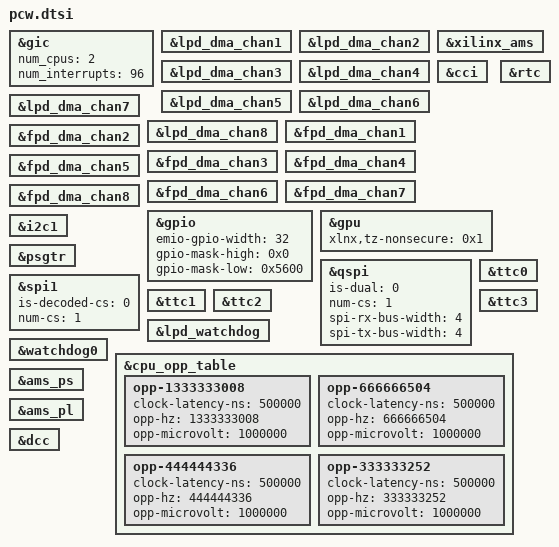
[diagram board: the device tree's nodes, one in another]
/*
 * CAUTION: This file is automatically generated by Xilinx.
 * Version: XSCT 2024.1
 * Today is: Thu Nov  7 23:48:31 2024
 */


&gic {
	num_cpus = <2>;
	num_interrupts = <96>;
};
&lpd_dma_chan1 {
	status = "okay";
};
&lpd_dma_chan2 {
	status = "okay";
};
&lpd_dma_chan3 {
	status = "okay";
};
&lpd_dma_chan4 {
	status = "okay";
};
&lpd_dma_chan5 {
	status = "okay";
};
&lpd_dma_chan6 {
	status = "okay";
};
&lpd_dma_chan7 {
	status = "okay";
};
&lpd_dma_chan8 {
	status = "okay";
};
&xilinx_ams {
	status = "okay";
};
&cci {
	status = "okay";
};
&fpd_dma_chan1 {
	status = "okay";
};
&fpd_dma_chan2 {
	status = "okay";
};
&fpd_dma_chan3 {
	status = "okay";
};
&fpd_dma_chan4 {
	status = "okay";
};
&fpd_dma_chan5 {
	status = "okay";
};
&fpd_dma_chan6 {
	status = "okay";
};
&fpd_dma_chan7 {
	status = "okay";
};
&fpd_dma_chan8 {
	status = "okay";
};
&gpio {
	emio-gpio-width = <32>;
	gpio-mask-high = <0x0>;
	gpio-mask-low = <0x5600>;
	status = "okay";
};
&gpu {
	status = "okay";
	xlnx,tz-nonsecure = <0x1>;
};
&i2c1 {
	status = "okay";
};
&qspi {
	is-dual = <0>;
	num-cs = <1>;
	spi-rx-bus-width = <4>;
	spi-tx-bus-width = <4>;
	status = "okay";
};
&rtc {
	status = "okay";
};
&psgtr {
	status = "okay";
};
&spi1 {
	is-decoded-cs = <0>;
	num-cs = <1>;
	status = "okay";
};
&ttc0 {
	status = "okay";
};
&ttc1 {
	status = "okay";
};
&ttc2 {
	status = "okay";
};
&ttc3 {
	status = "okay";
};
&lpd_watchdog {
	status = "okay";
};
&watchdog0 {
	status = "okay";
};
&cpu_opp_table {
	/delete-node/ opp00 ;
	/delete-node/ opp01 ;
	/delete-node/ opp02 ;
	/delete-node/ opp03 ;
	opp-1333333008 {
		clock-latency-ns = <500000>;
		opp-hz = /bits/ 64 <1333333008>;
		opp-microvolt = <1000000>;
	};
	opp-666666504 {
		clock-latency-ns = <500000>;
		opp-hz = /bits/ 64 <666666504>;
		opp-microvolt = <1000000>;
	};
	opp-444444336 {
		clock-latency-ns = <500000>;
		opp-hz = /bits/ 64 <444444336>;
		opp-microvolt = <1000000>;
	};
	opp-333333252 {
		clock-latency-ns = <500000>;
		opp-hz = /bits/ 64 <333333252>;
		opp-microvolt = <1000000>;
	};
};
&ams_ps {
	status = "okay";
};
&ams_pl {
	status = "okay";
};
&dcc {
	status = "okay";
};
